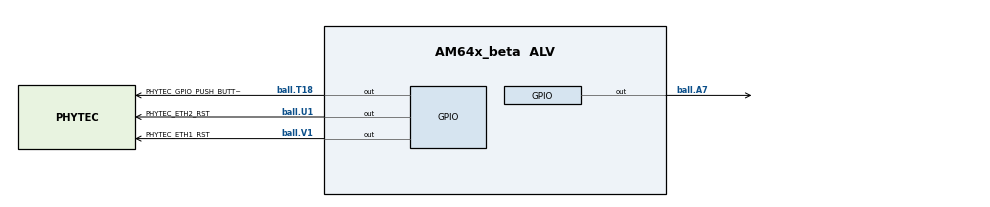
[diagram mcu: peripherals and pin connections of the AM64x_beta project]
/**
 * @cliArgs --device "AM64x_beta" --package "ALV" --part "Default" --context "r5fss0-0" --product "MCU_PLUS_SDK_AM64x@08.05.00"
 * @versions {"tool":"1.14.0+2667"}
 */

/**
 * Import the modules used in this configuration.
 */
const eeprom     = scripting.addModule("/board/eeprom/eeprom", {}, false);
const eeprom1    = eeprom.addInstance();
const gpio       = scripting.addModule("/drivers/gpio/gpio", {}, false);
const gpio1      = gpio.addInstance();
const gpio2      = gpio.addInstance();
const gpio3      = gpio.addInstance();
const gpio4      = gpio.addInstance();
const i2c        = scripting.addModule("/drivers/i2c/i2c", {}, false);
const i2c1       = i2c.addInstance();
const i2c2       = i2c.addInstance();
const pruicss    = scripting.addModule("/drivers/pruicss/pruicss", {}, false);
const pruicss1   = pruicss.addInstance();
const debug_log  = scripting.addModule("/kernel/dpl/debug_log");
const mpu_armv7  = scripting.addModule("/kernel/dpl/mpu_armv7", {}, false);
const mpu_armv71 = mpu_armv7.addInstance();
const mpu_armv72 = mpu_armv7.addInstance();
const mpu_armv73 = mpu_armv7.addInstance();
const mpu_armv74 = mpu_armv7.addInstance();
const mpu_armv75 = mpu_armv7.addInstance();
const mpu_armv76 = mpu_armv7.addInstance();
const mpu_armv77 = mpu_armv7.addInstance();
const enet_icss  = scripting.addModule("/networking/enet_icss/enet_icss", {}, false);
const enet_icss1 = enet_icss.addInstance();

/**
 * Write custom configuration values to the imported modules.
 */
eeprom1.$name = "CONFIG_EEPROM0";

gpio1.$name                    = "CONFIG_GPIO0";
gpio1.pinDir                   = "OUTPUT";
gpio1.useMcuDomainPeripherals  = true;
gpio1.MCU_GPIO.$assign         = "MCU_GPIO0";
gpio1.MCU_GPIO.gpioPin.$assign = "ball.A7";

gpio2.$name                = "PHYTEC_ETH1_RST";
gpio2.pinDir               = "OUTPUT";
gpio2.GPIO.gpioPin.$assign = "ball.V1";

gpio3.$name                = "PHYTEC_ETH2_RST";
gpio3.pinDir               = "OUTPUT";
gpio3.GPIO.gpioPin.$assign = "ball.U1";

gpio4.$name                = "PHYTEC_GPIO_PUSH_BUTTON";
gpio4.GPIO.gpioPin.$assign = "ball.T18";

i2c1.$name               = "CONFIG_I2C0";
eeprom1.peripheralDriver = i2c1;
i2c1.enableIntr          = false;
i2c1.bitRate             = "100KHZ";
i2c1.I2C.$assign         = "I2C0";
i2c1.I2C.SCL.$assign     = "ball.A18";
i2c1.I2C.SDA.$assign     = "ball.B18";

i2c2.$name           = "CONFIG_I2C1";
i2c2.enableIntr      = false;
i2c2.bitRate         = "100KHZ";
i2c2.I2C.$assign     = "I2C1";
i2c2.I2C.SCL.$assign = "ball.C18";
i2c2.I2C.SDA.$assign = "ball.B19";

debug_log.enableUartLog      = true;
debug_log.enableCssLog       = false;
debug_log.uartLog.$name      = "CONFIG_UART0";
debug_log.uartLog.intrEnable = "DISABLE";

mpu_armv71.$name             = "CONFIG_MPU_REGION0";
mpu_armv71.size              = 31;
mpu_armv71.attributes        = "Device";
mpu_armv71.accessPermissions = "Supervisor RD+WR, User RD";
mpu_armv71.allowExecute      = false;

mpu_armv72.$name             = "CONFIG_MPU_REGION1";
mpu_armv72.size              = 15;
mpu_armv72.accessPermissions = "Supervisor RD+WR, User RD";

mpu_armv73.$name             = "CONFIG_MPU_REGION2";
mpu_armv73.baseAddr          = 0x41010000;
mpu_armv73.size              = 15;
mpu_armv73.accessPermissions = "Supervisor RD+WR, User RD";

mpu_armv74.$name             = "CONFIG_MPU_REGION3";
mpu_armv74.accessPermissions = "Supervisor RD+WR, User RD";
mpu_armv74.baseAddr          = 0x70000000;
mpu_armv74.size              = 23;

mpu_armv75.$name             = "CONFIG_MPU_REGION4";
mpu_armv75.accessPermissions = "Supervisor RD+WR, User RD";
mpu_armv75.baseAddr          = 0x80000000;
mpu_armv75.size              = 31;

mpu_armv76.$name             = "CONFIG_MPU_REGION5";
mpu_armv76.accessPermissions = "Supervisor RD+WR, User RD";
mpu_armv76.baseAddr          = 0xA5000000;
mpu_armv76.size              = 23;
mpu_armv76.attributes        = "NonCached";

mpu_armv77.$name    = "CONFIG_MPU_REGION6";
mpu_armv77.size     = 27;
mpu_armv77.baseAddr = 0x60000000;

enet_icss1.$name                              = "CONFIG_ENET_ICSS0";
enet_icss1.GigabitSupportEnable               = false;
enet_icss1.QoS                                = 3;
enet_icss1.instance                           = "ICSSG0";
enet_icss1.customBoardEnable                  = true;
enet_icss1.mdioMode                           = "MDIO_MODE_NORMAL";
enet_icss1.mdioPollEnMask                     = ["1","2"];
enet_icss1.ExternalPhyMgmtEnable              = true;
enet_icss1.LargePoolPktCount                  = 32;
enet_icss1.txDmaChannel[0].$name              = "ENET_DMA_TX_CH0";
enet_icss1.rxDmaChannel.create(2);
enet_icss1.rxDmaChannel[0].$name              = "ENET_DMA_RX_CH0";
enet_icss1.rxDmaChannel[0].PacketsCount       = 8;
enet_icss1.rxDmaChannel[1].$name              = "ENET_DMA_RX_CH1";
enet_icss1.rxDmaChannel[1].chIdx              = 1;
enet_icss1.rxDmaChannel[1].AllocMacAddr       = false;
enet_icss1.rxDmaChannel[1].PacketsCount       = 8;
enet_icss1.PRU_ICSSG0_IEP.EDC_LATCH_IN0.$used = false;
enet_icss1.PRU_ICSSG0_IEP.EDC_SYNC_OUT0.$used = false;
enet_icss1.PRU_ICSSG0_MII_G_RT.MII0_COL.$used = false;
enet_icss1.PRU_ICSSG0_MII_G_RT.MII0_CRS.$used = false;

enet_icss1.icss                          = pruicss1;
pruicss1.$name                           = "CONFIG_PRU_ICSS1";
pruicss1.AdditionalICSSSettings[0].$name = "CONFIG_PRU_ICSS_IO0";
pruicss1.intcMapping.create(1);
pruicss1.intcMapping[0].$name            = "CONFIG_ICSS0_INTC_MAPPING0";
pruicss1.intcMapping[0].event            = "41";
pruicss1.intcMapping[0].channel          = "7";
pruicss1.intcMapping[0].host             = "8";

const udma         = scripting.addModule("/drivers/udma/udma", {}, false);
const udma1        = udma.addInstance({}, false);
enet_icss1.udmaDrv = udma1;

/**
 * These are the reserved peripherals and settings in this configuration
 */
const iSYSTEM1            = scripting.addPeripheral("SYSTEM");
iSYSTEM1.$name            = "MySYSTEM1";
iSYSTEM1.SYNC0_OUT.$used  = false;
iSYSTEM1.SYNC1_OUT.$used  = false;
iSYSTEM1.SYNC2_OUT.$used  = false;
iSYSTEM1.SYNC3_OUT.$used  = false;
iSYSTEM1.SYSCLKOUT0.$used = false;

/**
 * Pinmux solution for unlocked pins/peripherals. This ensures that minor changes to the automatic solver in a future
 * version of the tool will not impact the pinmux you originally saw.  These lines can be completely deleted in order to
 * re-solve from scratch.
 */
gpio2.GPIO.$suggestSolution                                 = "GPIO1";
gpio3.GPIO.$suggestSolution                                 = "GPIO1";
gpio4.GPIO.$suggestSolution                                 = "GPIO0";
debug_log.uartLog.UART.$suggestSolution                     = "USART0";
debug_log.uartLog.UART.RXD.$suggestSolution                 = "ball.D15";
debug_log.uartLog.UART.TXD.$suggestSolution                 = "ball.C16";
enet_icss1.PRU_ICSSG0_MDIO.$suggestSolution                 = "PRU_ICSSG0_MDIO0";
enet_icss1.PRU_ICSSG0_MDIO.MDC.$suggestSolution             = "ball.P3";
enet_icss1.PRU_ICSSG0_MDIO.MDIO.$suggestSolution            = "ball.P2";
enet_icss1.PRU_ICSSG0_IEP.$suggestSolution                  = "PRU_ICSSG0_IEP0";
enet_icss1.PRU_ICSSG0_MII_G_RT.$suggestSolution             = "PRU_ICSSG0_MII_G_RT";
enet_icss1.PRU_ICSSG0_MII_G_RT.MII0_RXD0.$suggestSolution   = "ball.Y1";
enet_icss1.PRU_ICSSG0_MII_G_RT.MII0_RXD1.$suggestSolution   = "ball.R4";
enet_icss1.PRU_ICSSG0_MII_G_RT.MII0_RXD2.$suggestSolution   = "ball.U2";
enet_icss1.PRU_ICSSG0_MII_G_RT.MII0_RXD3.$suggestSolution   = "ball.V2";
enet_icss1.PRU_ICSSG0_MII_G_RT.MII0_RXDV.$suggestSolution   = "ball.AA2";
enet_icss1.PRU_ICSSG0_MII_G_RT.MII0_RXER.$suggestSolution   = "ball.R3";
enet_icss1.PRU_ICSSG0_MII_G_RT.MII0_RXLINK.$suggestSolution = "ball.T2";
enet_icss1.PRU_ICSSG0_MII_G_RT.MII0_TXD0.$suggestSolution   = "ball.Y3";
enet_icss1.PRU_ICSSG0_MII_G_RT.MII0_TXD1.$suggestSolution   = "ball.AA3";
enet_icss1.PRU_ICSSG0_MII_G_RT.MII0_TXD2.$suggestSolution   = "ball.R6";
enet_icss1.PRU_ICSSG0_MII_G_RT.MII0_TXD3.$suggestSolution   = "ball.V4";
enet_icss1.PRU_ICSSG0_MII_G_RT.MII0_TXEN.$suggestSolution   = "ball.T5";
enet_icss1.PRU_ICSSG0_MII_G_RT.MII1_COL.$suggestSolution    = "ball.Y5";
enet_icss1.PRU_ICSSG0_MII_G_RT.MII1_CRS.$suggestSolution    = "ball.V6";
enet_icss1.PRU_ICSSG0_MII_G_RT.MII1_RXD0.$suggestSolution   = "ball.Y2";
enet_icss1.PRU_ICSSG0_MII_G_RT.MII1_RXD1.$suggestSolution   = "ball.W2";
enet_icss1.PRU_ICSSG0_MII_G_RT.MII1_RXD2.$suggestSolution   = "ball.V3";
enet_icss1.PRU_ICSSG0_MII_G_RT.MII1_RXD3.$suggestSolution   = "ball.T4";
enet_icss1.PRU_ICSSG0_MII_G_RT.MII1_RXDV.$suggestSolution   = "ball.W3";
enet_icss1.PRU_ICSSG0_MII_G_RT.MII1_RXER.$suggestSolution   = "ball.P4";
enet_icss1.PRU_ICSSG0_MII_G_RT.MII1_RXLINK.$suggestSolution = "ball.R1";
enet_icss1.PRU_ICSSG0_MII_G_RT.MII1_TXD0.$suggestSolution   = "ball.W4";
enet_icss1.PRU_ICSSG0_MII_G_RT.MII1_TXD1.$suggestSolution   = "ball.Y4";
enet_icss1.PRU_ICSSG0_MII_G_RT.MII1_TXD2.$suggestSolution   = "ball.T6";
enet_icss1.PRU_ICSSG0_MII_G_RT.MII1_TXD3.$suggestSolution   = "ball.U6";
enet_icss1.PRU_ICSSG0_MII_G_RT.MII1_TXEN.$suggestSolution   = "ball.U5";
enet_icss1.PRU_ICSSG0_MII_G_RT.MII_MR0_CLK.$suggestSolution = "ball.T3";
enet_icss1.PRU_ICSSG0_MII_G_RT.MII_MR1_CLK.$suggestSolution = "ball.R5";
enet_icss1.PRU_ICSSG0_MII_G_RT.MII_MT0_CLK.$suggestSolution = "ball.U4";
enet_icss1.PRU_ICSSG0_MII_G_RT.MII_MT1_CLK.$suggestSolution = "ball.AA4";
iSYSTEM1.$suggestSolution                                   = "SYSTEM0";
iSYSTEM1.CLKOUT0.$suggestSolution                           = "ball.U13";
iSYSTEM1.EXTINTn.$suggestSolution                           = "ball.C19";
iSYSTEM1.EXT_REFCLK1.$suggestSolution                       = "ball.A19";
iSYSTEM1.FCLK_MUX.$suggestSolution                          = "ball.R17";
iSYSTEM1.OBSCLK0.$suggestSolution                           = "ball.D17";
iSYSTEM1.PORz_OUT.$suggestSolution                          = "ball.E17";
iSYSTEM1.RESET_REQz.$suggestSolution                        = "ball.E18";
iSYSTEM1.RESETSTATz.$suggestSolution                        = "ball.F16";
